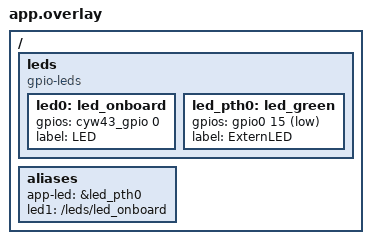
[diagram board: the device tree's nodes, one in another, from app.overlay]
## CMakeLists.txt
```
cmake_minimum_required(VERSION 3.20.0)

find_package(Zephyr REQUIRED)
project(blinky)

target_sources(app PRIVATE src/main.cpp)
```

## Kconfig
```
menu "Blink Led Options"
    config APP_HEARTBEAT_PERIOD_MS
        int "APP_HEARTBEAT_PERIOD_MS"
        default 500
        range 100 2000
endmenu

source "Kconfig.zephyr"
```

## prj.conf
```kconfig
CONFIG_GPIO=y
CONFIG_LOG=y

# Needed for RPI Pico W
CONFIG_CYW43439=y
CONFIG_NETWORKING=y
CONFIG_WIFI=y
CONFIG_WIFI_AIROC=y
CONFIG_GPIO_CYW43=y
CONFIG_ENTROPY_GENERATOR=y
CONFIG_TEST_RANDOM_GENERATOR=y
```

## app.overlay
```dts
// raspbery pi pico
/ {
	leds {
		compatible = "gpio-leds";

		led0: led_onboard {
			gpios = <&cyw43_gpio 0 GPIO_ACTIVE_HIGH>;
			label = "LED";
		};

        led_pth0: led_green {
            gpios = <&gpio0 15 GPIO_ACTIVE_LOW>;
            label = "ExternLED";
        };
	};

    aliases {
        app-led = &led_pth0;
        led1 = "/leds/led_onboard";
    };
};
```

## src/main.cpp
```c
#include <zephyr/drivers/gpio.h>
#include <zephyr/kernel.h>

static const struct gpio_dt_spec led = GPIO_DT_SPEC_GET(DT_ALIAS(app_led), gpios);
static const struct gpio_dt_spec onboard = GPIO_DT_SPEC_GET(DT_ALIAS(led1), gpios);

int main(void)
{
    bool led_state = true;
    int32_t sleep_duration_ms = 1000;

    if (!gpio_is_ready_dt(&led)) return 0;
    if (!gpio_is_ready_dt(&onboard)) return 0;

    if (gpio_pin_configure_dt(&led, GPIO_OUTPUT_INACTIVE) < 0) return 0;
    if (gpio_pin_configure_dt(&onboard, GPIO_OUTPUT_ACTIVE) < 0) return 0;

    #ifdef CONFIG_DT_BLINK_LED
        sleep_duration_ms = CONFIG_APP_HEARTBEAT_PERIOD_MS;
    #endif // CONFIG_DT_BLINK_LED

    while (1) {
        if (gpio_pin_toggle_dt(&led) < 0) return 0;
        if (gpio_pin_toggle_dt(&onboard) < 0) return 0;

        led_state = !led_state;
        k_msleep(sleep_duration_ms);
    }
    return 0;
}
```
